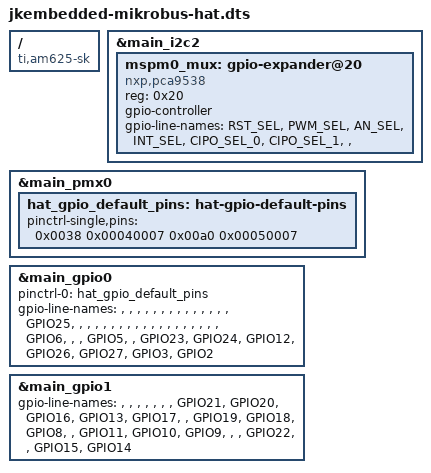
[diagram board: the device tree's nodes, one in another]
/dts-v1/;
/plugin/;

/ {
	compatible = "ti,am625-sk", "ti,am625";

	fragment@0 {
		/* SK-AM62 40-pin expansion header I2C is the SoC I2C2 bus. */
		target = <&main_i2c2>;
		__overlay__ {
			#address-cells = <1>;
			#size-cells = <0>;

			mspm0_mux: gpio-expander@20 {
				compatible = "nxp,pca9538";
				reg = <0x20>;
				gpio-controller;
				#gpio-cells = <2>;
				gpio-line-names =
					"RST_SEL",
					"PWM_SEL",
					"AN_SEL",
					"INT_SEL",
					"CIPO_SEL_0",
					"CIPO_SEL_1",
					"",
					"";
				status = "okay";
			};
		};
	};

	fragment@1 {
		target = <&main_pmx0>;
		__overlay__ {
			hat_gpio_default_pins: hat-gpio-default-pins {
				pinctrl-single,pins = <
					0x0038 0x00040007 /* HAT pin 22 / GPIO25 / GPIO0_14 input, pull-down */
					0x00a0 0x00050007 /* HAT pin 18 / GPIO24 / GPIO0_39 input */
				>;
			};
		};
	};

	fragment@2 {
		target = <&main_gpio0>;
		__overlay__ {
			pinctrl-names = "default";
			pinctrl-0 = <&hat_gpio_default_pins>;
			gpio-line-names = "", "", "", "", "", "", "", "", "", "",
				"", "", "", "", "GPIO25", "", "", "", "", "",
				"", "", "", "", "", "", "", "", "", "",
				"", "", "", "GPIO6", "", "", "GPIO5", "", "GPIO23",
				"GPIO24", "GPIO12", "GPIO26", "GPIO27", "GPIO3", "GPIO2";
			status = "okay";
		};
	};

	fragment@3 {
		target = <&main_gpio1>;
		__overlay__ {
			gpio-line-names = "", "", "", "", "", "", "", "GPIO21",
				"GPIO20", "GPIO16", "GPIO13", "GPIO17", "", "GPIO19",
				"GPIO18", "GPIO8", "", "GPIO11", "GPIO10", "GPIO9",
				"", "", "GPIO22", "", "GPIO15", "GPIO14";
			status = "okay";
		};
	};
};
